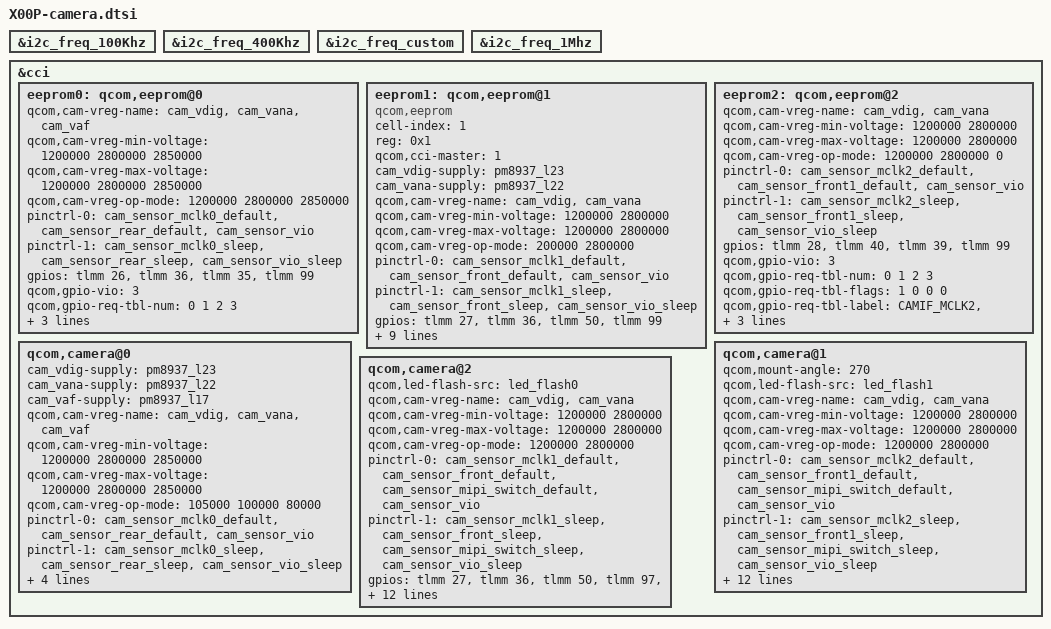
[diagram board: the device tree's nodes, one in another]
/*
 * Copyright (c) 2015-2017, The Linux Foundation. All rights reserved.
 *
 * This program is free software; you can redistribute it and/or modify
 * it under the terms of the GNU General Public License version 2 and
 * only version 2 as published by the Free Software Foundation.
 *
 * This program is distributed in the hope that it will be useful,
 * but WITHOUT ANY WARRANTY; without even the implied warranty of
 * MERCHANTABILITY or FITNESS FOR A PARTICULAR PURPOSE.  See the
 * GNU General Public License for more details.
 */

/* msm8937-camera */

&i2c_freq_100Khz {
	status = "okay";
};

&i2c_freq_400Khz {
	status = "okay";
};

&i2c_freq_custom {
	status = "okay";
};

&i2c_freq_1Mhz {
	status = "okay";
};

/* msm8937-camera-sensor-qrd */

&cci {

	eeprom0: qcom,eeprom@0 {
		/delete-property/ cam_vio-supply;
		qcom,cam-vreg-name = "cam_vdig", "cam_vana",
						"cam_vaf";
		qcom,cam-vreg-min-voltage = <1200000 2800000 2850000>;
		qcom,cam-vreg-max-voltage = <1200000 2800000 2850000>;
		qcom,cam-vreg-op-mode = <1200000 2800000 2850000>;
		pinctrl-0 = <&cam_sensor_mclk0_default
				&cam_sensor_rear_default
				&cam_sensor_vio>;
		pinctrl-1 = <&cam_sensor_mclk0_sleep &cam_sensor_rear_sleep &cam_sensor_vio_sleep>;
		gpios = <&tlmm 26 0>,
			<&tlmm 36 0>,
			<&tlmm 35 0>,
			<&tlmm 99 0>;
		qcom,gpio-vio = <3>;
		qcom,gpio-req-tbl-num = <0 1 2 3>;
		qcom,gpio-req-tbl-flags = <1 0 0 0>;
		qcom,gpio-req-tbl-label = "CAMIF_MCLK0",
			"CAM_RESET0",
			"CAM_STANDBY0",
			"CAM_VIO";
	};

	eeprom1: qcom,eeprom@1 {
		cell-index = <1>;
		reg = <0x1>;
		/delete-property/ qcom,eeprom-name;

		/delete-property/ qcom,slave-addr;
		/delete-property/ qcom,num-blocks;
		/delete-property/ qcom,page0;
		/delete-property/ qcom,poll0;
		/delete-property/ qcom,mem1;
		/delete-property/ qcom,page1;
		/delete-property/ qcom,poll1;
		/delete-property/ qcom,mem1;
		/delete-property/ qcom,page2;
		/delete-property/ qcom,poll2;
		/delete-property/ qcom,mem2;
		/delete-property/ qcom,page3;
		/delete-property/ qcom,poll3;
		/delete-property/ qcom,mem3;
		/delete-property/ qcom,page4;
		/delete-property/ qcom,poll4;
		/delete-property/ qcom,mem4;
		/delete-property/ qcom,page5;
		/delete-property/ qcom,poll5;
		/delete-property/ qcom,mem5;
		/delete-property/ qcom,page6;
		/delete-property/ qcom,poll6;
		/delete-property/ qcom,mem6;
		/delete-property/ qcom,page7;
		/delete-property/ qcom,poll7;
		/delete-property/ qcom,mem7;


		compatible = "qcom,eeprom";
		qcom,cci-master = <1>;

		cam_vdig-supply = <&pm8937_l23>;
		cam_vana-supply = <&pm8937_l22>;
		/delete-property/ cam_vio-supply;
		/delete-property/ cam_vaf-supply;

		qcom,cam-vreg-name = "cam_vdig", "cam_vana";
		qcom,cam-vreg-min-voltage = <1200000 2800000>;
		qcom,cam-vreg-max-voltage = <1200000 2800000>;
		qcom,cam-vreg-op-mode = <200000 2800000>;
		/delete-property/ qcom,gpio-no-mux;
		pinctrl-names = "cam_default", "cam_suspend";
		pinctrl-0 = <&cam_sensor_mclk1_default
			&cam_sensor_front_default
			&cam_sensor_vio>;
		pinctrl-1 = <&cam_sensor_mclk1_sleep &cam_sensor_front_sleep &cam_sensor_vio_sleep>;
		gpios = <&tlmm 27 0>,
			<&tlmm 36 0>,
			<&tlmm 50 0>,
			<&tlmm 99 0>;
		qcom,gpio-reset = <1>;
		qcom,gpio-standby = <2>;
		qcom,gpio-vio = <3>;
		qcom,gpio-req-tbl-num = <0 1 2 3>;
		qcom,gpio-req-tbl-flags = <1 0 0 0>;
		qcom,gpio-req-tbl-label = "CAMIF_MCLK1",
					  "CAM_RESET1",
					  "CAM_STANDBY1",
					  "CAM_VIO";
		clocks = <&clock_gcc clk_mclk1_clk_src>,
			<&clock_gcc clk_gcc_camss_mclk1_clk>;
	};

	eeprom2: qcom,eeprom@2 {
		/delete-property/ cam_vio-supply;
		/delete-property/ cam_vaf-supply;
		qcom,cam-vreg-name = "cam_vdig", "cam_vana";
		qcom,cam-vreg-min-voltage = <1200000 2800000>;
		qcom,cam-vreg-max-voltage = <1200000 2800000>;
		qcom,cam-vreg-op-mode = <1200000 2800000 0>;
		pinctrl-0 = <&cam_sensor_mclk2_default
				&cam_sensor_front1_default
				&cam_sensor_vio>;
		pinctrl-1 = <&cam_sensor_mclk2_sleep &cam_sensor_front1_sleep &cam_sensor_vio_sleep>;
		gpios = <&tlmm 28 0>,
			<&tlmm 40 0>,
			<&tlmm 39 0>,
			<&tlmm 99 0>;
		qcom,gpio-vio = <3>;
		qcom,gpio-req-tbl-num = <0 1 2 3>;
		qcom,gpio-req-tbl-flags = <1 0 0 0>;
		qcom,gpio-req-tbl-label = "CAMIF_MCLK2",
			"CAM_RESET2",
			"CAM_STANDBY2",
			"CAM_VIO";
		clocks = <&clock_gcc clk_mclk2_clk_src>,
				<&clock_gcc clk_gcc_camss_mclk2_clk>;
	};

	qcom,camera@0 {
		cam_vdig-supply = <&pm8937_l23>;
		cam_vana-supply = <&pm8937_l22>;
		/delete-property/ cam_vio-supply;
		cam_vaf-supply = <&pm8937_l17>;
		qcom,cam-vreg-name = "cam_vdig", "cam_vana", "cam_vaf";
		qcom,cam-vreg-min-voltage = <1200000 2800000 2850000>;
		qcom,cam-vreg-max-voltage = <1200000 2800000 2850000>;
		qcom,cam-vreg-op-mode = <105000 100000 80000>;
		pinctrl-0 = <&cam_sensor_mclk0_default
				&cam_sensor_rear_default
				&cam_sensor_vio>;
		pinctrl-1 = <&cam_sensor_mclk0_sleep &cam_sensor_rear_sleep
				&cam_sensor_vio_sleep>;
		gpios = <&tlmm 26 0>,
			<&tlmm 38 0>,
			<&tlmm 35 0>,
			<&tlmm 99 0>;
		qcom,gpio-vio = <3>;
		qcom,gpio-req-tbl-label = "CAMIF_MCLK0",
			"CAM_RESET0",
			"CAM_STANDBY0",
			"CAM_VIO";
	};

	qcom,camera@1 {
		qcom,mount-angle = <270>;
		qcom,led-flash-src = <&led_flash1>;
		/delete-property/ cam_vio-supply;
		/delete-property/ cam_vaf-supply;
		qcom,cam-vreg-name = "cam_vdig", "cam_vana";
		qcom,cam-vreg-min-voltage = <1200000 2800000>;
		qcom,cam-vreg-max-voltage = <1200000 2800000>;
		qcom,cam-vreg-op-mode = <1200000 2800000>;
		pinctrl-0 = <&cam_sensor_mclk2_default
				&cam_sensor_front1_default
				&cam_sensor_mipi_switch_default
				&cam_sensor_vio>;
		pinctrl-1 = <&cam_sensor_mclk2_sleep
				&cam_sensor_front1_sleep
				&cam_sensor_mipi_switch_sleep
				&cam_sensor_vio_sleep>;
		gpios = <&tlmm 28 0>,
			<&tlmm 40 0>,
			<&tlmm 39 0>,
			<&tlmm 97 0>,
			<&tlmm 96 0>,
			<&tlmm 99 0>;
		qcom,gpio-custom1 = <3>;
		qcom,gpio-custom2 = <4>;
		qcom,gpio-vio = <5>;
		qcom,gpio-req-tbl-num = <0 1 2 3 4 5>;
		qcom,gpio-req-tbl-flags = <1 0 0 0 0 0>;
		qcom,gpio-req-tbl-label = "CAMIF_MCLK2",
			"CAM_RESET2",
			"CAM_STANDBY2",
			"CAM_MIPIEN",
			"CAM_MIPISEL",
			"CAM_VIO";
		clocks = <&clock_gcc clk_mclk2_clk_src>,
				<&clock_gcc clk_gcc_camss_mclk2_clk>;
	};

	qcom,camera@2 {
		qcom,led-flash-src = <&led_flash0>;
		/delete-property/ qcom,actuator-src;
		/delete-property/ cam_vio-supply;
		/delete-property/ cam_vaf-supply;
		qcom,cam-vreg-name = "cam_vdig", "cam_vana";
		qcom,cam-vreg-min-voltage = <1200000 2800000>;
		qcom,cam-vreg-max-voltage = <1200000 2800000>;
		qcom,cam-vreg-op-mode = <1200000 2800000>;
		pinctrl-0 = <&cam_sensor_mclk1_default
				&cam_sensor_front_default
				&cam_sensor_mipi_switch_default
				&cam_sensor_vio>;
		pinctrl-1 = <&cam_sensor_mclk1_sleep
				&cam_sensor_front_sleep
				&cam_sensor_mipi_switch_sleep
				&cam_sensor_vio_sleep>;
		gpios = <&tlmm 27 0>,
			<&tlmm 36 0>,
			<&tlmm 50 0>,
			<&tlmm 97 0>,
			<&tlmm 96 0>,
			<&tlmm 99 0>;
		qcom,gpio-custom1 = <3>;
		qcom,gpio-custom2 = <4>;
		qcom,gpio-vio = <5>;
		qcom,gpio-req-tbl-num = <0 1 2 3 4 5>;
		qcom,gpio-req-tbl-flags = <1 0 0 0 0 0>;
		qcom,gpio-req-tbl-label = "CAMIF_MCLK1",
					  "CAM_RESET1",
					  "CAM_STANDBY1",
					  "CAM_MIPIEN",
					  "CAM_MIPISEL",
					  "CAM_VIO";
		qcom,cci-master = <1>;
		clocks = <&clock_gcc clk_mclk1_clk_src>,
			<&clock_gcc clk_gcc_camss_mclk1_clk>;
	};
};
